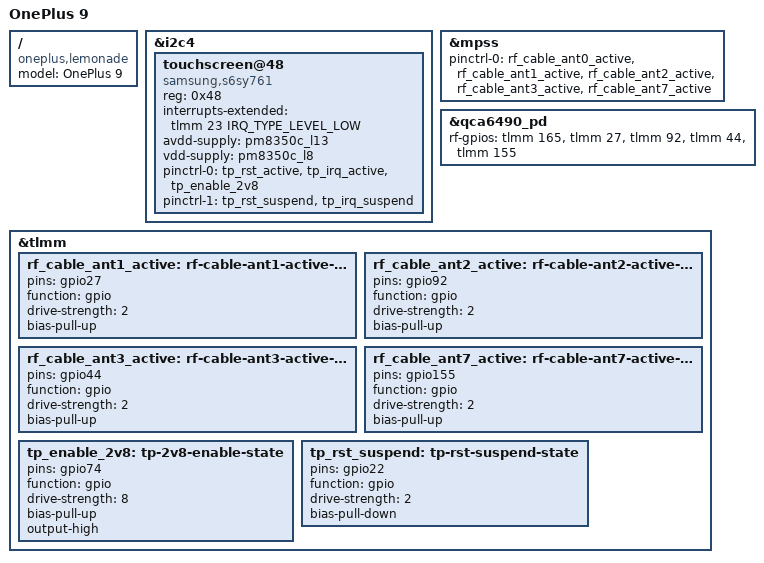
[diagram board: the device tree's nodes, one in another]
// SPDX-License-Identifier: BSD-3-Clause
/*
 * Copyright (c) 2023 Igalia S.L.
 * Authors:
 *	Nia Espera <nespera@igalia.com>
 */

/dts-v1/;

#include "sm8350-oneplus-common.dtsi"

/ {
	compatible = "oneplus,lemonade", "qcom,sm8350";
	model = "OnePlus 9";
};

&i2c4 {
	touchscreen@48 {
		compatible = "samsung,s6sy761";
		reg = <0x48>;
		interrupts-extended = <&tlmm 23 IRQ_TYPE_LEVEL_LOW>;

		avdd-supply = <&pm8350c_l13>;
		vdd-supply = <&pm8350c_l8>;

		pinctrl-0 = <&tp_rst_active>, <&tp_irq_active>, <&tp_enable_2v8>;
		pinctrl-1 = <&tp_rst_suspend>, <&tp_irq_suspend>;
		pinctrl-names = "default", "sleep";
	};
};

&mpss {
	pinctrl-0 = <&rf_cable_ant0_active>,
		    <&rf_cable_ant1_active>,
		    <&rf_cable_ant2_active>,
		    <&rf_cable_ant3_active>,
		    <&rf_cable_ant7_active>;
	pinctrl-names = "default";
	status = "okay";
};

&qca6490_pd {
	rf-gpios = <&tlmm 165 0>,
		   <&tlmm 27 0>,
		   <&tlmm 92 0>,
		   <&tlmm 44 0>,
		   <&tlmm 155 0>;
	status = "okay";
};

&tlmm {
	/* Modem antenna pins exclusive to lemonade */
	rf_cable_ant1_active: rf-cable-ant1-active-state {
		pins = "gpio27";
		function = "gpio";
		drive-strength = <2>;
		bias-pull-up;
	};

	rf_cable_ant2_active: rf-cable-ant2-active-state {
		pins = "gpio92";
		function = "gpio";
		drive-strength = <2>;
		bias-pull-up;
	};

	rf_cable_ant3_active: rf-cable-ant3-active-state {
		pins = "gpio44";
		function = "gpio";
		drive-strength = <2>;
		bias-pull-up;
	};

	rf_cable_ant7_active: rf-cable-ant7-active-state {
		pins = "gpio155";
		function = "gpio";
		drive-strength = <2>;
		bias-pull-up;
	};

	tp_enable_2v8: tp-2v8-enable-state {
		pins = "gpio74";
		function = "gpio";
		drive-strength = <8>;
		bias-pull-up;
		output-high;
	};

	tp_rst_suspend: tp-rst-suspend-state {
		pins = "gpio22";
		function = "gpio";
		drive-strength = <2>;
		bias-pull-down;
	};
};
